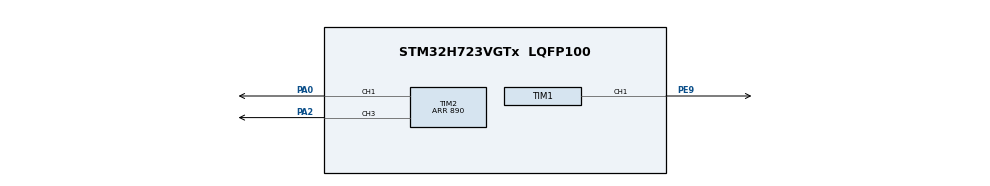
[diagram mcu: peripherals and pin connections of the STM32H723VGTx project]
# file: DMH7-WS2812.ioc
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CORTEX_M7.default_mode_Activation=1
Dma.Request0=TIM2_CH1
Dma.Request1=TIM2_CH3
Dma.Request2=TIM1_CH1
Dma.TIM1_CH1.2.Direction=DMA_MEMORY_TO_PERIPH
Dma.TIM1_CH1.2.EventEnable=DISABLE
Dma.TIM1_CH1.2.FIFOMode=DMA_FIFOMODE_DISABLE
Dma.TIM1_CH1.2.Instance=DMA1_Stream0
Dma.TIM1_CH1.2.MemDataAlignment=DMA_MDATAALIGN_HALFWORD
Dma.TIM1_CH1.2.MemInc=DMA_MINC_ENABLE
Dma.TIM1_CH1.2.Mode=DMA_NORMAL
Dma.TIM1_CH1.2.PeriphDataAlignment=DMA_PDATAALIGN_HALFWORD
Dma.TIM1_CH1.2.PeriphInc=DMA_PINC_DISABLE
Dma.TIM1_CH1.2.Polarity=HAL_DMAMUX_REQ_GEN_RISING
Dma.TIM1_CH1.2.Priority=DMA_PRIORITY_LOW
Dma.TIM1_CH1.2.RequestNumber=1
Dma.TIM1_CH1.2.SignalID=NONE
Dma.TIM1_CH1.2.SyncEnable=DISABLE
Dma.TIM1_CH1.2.SyncPolarity=HAL_DMAMUX_SYNC_NO_EVENT
Dma.TIM1_CH1.2.SyncRequestNumber=1
Dma.TIM1_CH1.2.SyncSignalID=NONE
Dma.TIM2_CH1.0.Direction=DMA_MEMORY_TO_PERIPH
Dma.TIM2_CH1.0.EventEnable=DISABLE
Dma.TIM2_CH1.0.FIFOMode=DMA_FIFOMODE_ENABLE
Dma.TIM2_CH1.0.FIFOThreshold=DMA_FIFO_THRESHOLD_FULL
Dma.TIM2_CH1.0.Instance=DMA2_Stream0
Dma.TIM2_CH1.0.MemBurst=DMA_MBURST_SINGLE
Dma.TIM2_CH1.0.MemDataAlignment=DMA_MDATAALIGN_HALFWORD
Dma.TIM2_CH1.0.MemInc=DMA_MINC_ENABLE
Dma.TIM2_CH1.0.Mode=DMA_CIRCULAR
Dma.TIM2_CH1.0.PeriphBurst=DMA_PBURST_SINGLE
Dma.TIM2_CH1.0.PeriphDataAlignment=DMA_PDATAALIGN_HALFWORD
Dma.TIM2_CH1.0.PeriphInc=DMA_PINC_DISABLE
Dma.TIM2_CH1.0.Polarity=HAL_DMAMUX_REQ_GEN_RISING
Dma.TIM2_CH1.0.Priority=DMA_PRIORITY_VERY_HIGH
Dma.TIM2_CH1.0.RequestNumber=1
Dma.TIM2_CH1.0.SignalID=NONE
Dma.TIM2_CH1.0.SyncEnable=DISABLE
Dma.TIM2_CH1.0.SyncPolarity=HAL_DMAMUX_SYNC_NO_EVENT
Dma.TIM2_CH1.0.SyncRequestNumber=1
Dma.TIM2_CH1.0.SyncSignalID=NONE
Dma.TIM2_CH3.1.Direction=DMA_MEMORY_TO_PERIPH
Dma.TIM2_CH3.1.EventEnable=DISABLE
Dma.TIM2_CH3.1.FIFOMode=DMA_FIFOMODE_ENABLE
Dma.TIM2_CH3.1.FIFOThreshold=DMA_FIFO_THRESHOLD_FULL
Dma.TIM2_CH3.1.Instance=DMA1_Stream1
Dma.TIM2_CH3.1.MemBurst=DMA_MBURST_SINGLE
Dma.TIM2_CH3.1.MemDataAlignment=DMA_MDATAALIGN_WORD
Dma.TIM2_CH3.1.MemInc=DMA_MINC_ENABLE
Dma.TIM2_CH3.1.Mode=DMA_CIRCULAR
Dma.TIM2_CH3.1.PeriphBurst=DMA_PBURST_SINGLE
Dma.TIM2_CH3.1.PeriphDataAlignment=DMA_PDATAALIGN_WORD
Dma.TIM2_CH3.1.PeriphInc=DMA_PINC_DISABLE
Dma.TIM2_CH3.1.Polarity=HAL_DMAMUX_REQ_GEN_RISING
Dma.TIM2_CH3.1.Priority=DMA_PRIORITY_VERY_HIGH
Dma.TIM2_CH3.1.RequestNumber=1
Dma.TIM2_CH3.1.SignalID=NONE
Dma.TIM2_CH3.1.SyncEnable=DISABLE
Dma.TIM2_CH3.1.SyncPolarity=HAL_DMAMUX_SYNC_NO_EVENT
Dma.TIM2_CH3.1.SyncRequestNumber=1
Dma.TIM2_CH3.1.SyncSignalID=NONE
Mcu.Family=STM32H7
Mcu.Name=STM32H723VGTx
Mcu.Package=LQFP100
NVIC.DMA1_Stream0_IRQn=true\:0\:0\:false\:false\:true\:false\:true\:true
NVIC.DMA1_Stream1_IRQn=true\:0\:0\:false\:false\:true\:false\:true\:true
NVIC.DMA2_Stream0_IRQn=true\:1\:0\:true\:false\:true\:false\:true\:true
NVIC.PriorityGroup=NVIC_PRIORITYGROUP_4
PA0.Signal=S_TIM2_CH1_ETR
PA2.Signal=S_TIM2_CH3
PE9.Signal=S_TIM1_CH1
PH0-OSC_IN.Mode=HSE-External-Oscillator
PH0-OSC_IN.Signal=RCC_OSC_IN
PH1-OSC_OUT.Mode=HSE-External-Oscillator
PH1-OSC_OUT.Signal=RCC_OSC_OUT
ProjectManager.HeapSize=0x200
ProjectManager.StackSize=0x400
ProjectManager.TargetToolchain=STM32CubeIDE
RCC.ADCFreq_Value=48375000
RCC.APB1Freq_Value=36000000
RCC.APB2Freq_Value=36000000
RCC.APB3Freq_Value=36000000
RCC.APB4Freq_Value=36000000
RCC.CortexFreq_Value=72000000
RCC.D1PPRE=RCC_APB3_DIV2
RCC.D2PPRE1=RCC_APB1_DIV2
RCC.D2PPRE2=RCC_APB2_DIV2
RCC.D3PPRE=RCC_APB4_DIV2
RCC.DIVM1=2
RCC.DIVN1=18
RCC.DIVP1=3
RCC.HCLKFreq_Value=72000000
RCC.HSE_VALUE=24000000
RCC.PLL2FRACN=0
RCC.PLL2_VCI_Range-AdvancedSettings=RCC_PLL2VCIRANGE_3
RCC.PLL3FRACN=0
RCC.PLLFRACN=0
RCC.PLLSourceVirtual=RCC_PLLSOURCE_HSE
RCC.SYSCLKFreq_VALUE=72000000
RCC.SYSCLKSource=RCC_SYSCLKSOURCE_PLLCLK
RCC.USART16Enable-ClockTree=true
RCC.USBFreq_Value=108000000
SH.S_TIM1_CH1.0=TIM1_CH1,PWM Generation1 CH1
SH.S_TIM2_CH1_ETR.0=TIM2_CH1,PWM Generation1 CH1
SH.S_TIM2_CH3.0=TIM2_CH3,PWM Generation3 CH3
TIM1.Channel-PWM\ Generation1\ CH1=TIM_CHANNEL_1
TIM1.Period=89
TIM2.Channel-PWM\ Generation1\ CH1=TIM_CHANNEL_1
TIM2.Channel-PWM\ Generation3\ CH3=TIM_CHANNEL_3
TIM2.Period=890
TIM2.Pulse-PWM\ Generation1\ CH1=20
TIM2.Pulse-PWM\ Generation3\ CH3=20
VP_MEMORYMAP_VS_MEMORYMAP.Mode=CurAppReg
board=custom

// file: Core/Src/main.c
/* USER CODE BEGIN Header */
/**
  ******************************************************************************
  * @file           : main.c
  * @brief          : Main program body
  ******************************************************************************
  * @attention
  *
  * Copyright (c) 2024 STMicroelectronics.
  * All rights reserved.
  *
  * This software is licensed under terms that can be found in the LICENSE file
  * in the root directory of this software component.
  * If no LICENSE file comes with this software, it is provided AS-IS.
  *
  ******************************************************************************
  */
/* USER CODE END Header */
#include "main.h"
#include "dma.h"
#include "memorymap.h"
#include "tim.h"
#include "gpio.h"

/* USER CODE BEGIN Includes */
#include "WS2812.h"
/* USER CODE END Includes */

void SystemClock_Config(void);

int main(void)
{

  /* MCU Configuration--------------------------------------------------------*/

  /* Reset of all peripherals, Initializes the Flash interface and the Systick. */
  HAL_Init();

  /* Configure the system clock */
  SystemClock_Config();

  /* Initialize all configured peripherals */
  MX_GPIO_Init();
  MX_DMA_Init();
  MX_TIM2_Init();
  MX_TIM1_Init();
  /* USER CODE BEGIN 2 */
  WS2812_Init();
  float circle_idx[][5] = {
    {8.4,0,15,44.5,78},
    {7.4,103,131.5,158.5,187.4},
    {6.4,211.5,235,258.5,283.4},
    {5.4,302.4,324.5,345.5,365.4},
    {4.4,383.4,400,417,435.4},
    {3.4,448.4,463,477,491},
    {2.4,501.4,512.5,523,532.4},
    {1.4,540,546.5,553,560},
    {0.4,566,568,570,573.6},
    {0,575,0,0,0},
  };
  // static uint16_t led_block[1][2] = {0};
  static uint16_t led_block[10*4+4][2] = {0};

  static uint32_t color = 0x00FF0000;

  WS2812_Start();
  /* USER CODE END 2 */

  /* Infinite loop */
  /* USER CODE BEGIN WHILE */
  while (1)
  {
    HAL_TIM_PWM_Stop_DMA(&htim1, TIM_CHANNEL_1);
    WS2812_Init();
    for (int i = 0; i < sizeof(circle_idx)/sizeof(circle_idx[0]); i++){
      for (int j = 0; j < sizeof(circle_idx[0])/sizeof(circle_idx[0][0]); j++){
        if(circle_idx[i][j+1] == 0.0) continue;
        led_block[i*4+j][0] = circle_idx[i][j+1] - circle_idx[i][0];
        led_block[i*4+j][1] = circle_idx[i][j+1] + circle_idx[i][0];
      }
    }
    uint8_t block_idx = 0,block_flag = 1;
    for (int i = 0; i < LED_NUM; i++){
      if( block_flag &&  i >= led_block[block_idx][0] && i <= led_block[block_idx][1])
        WS2812_Set(i, color);
      else
        WS2812_Set(i, 0x00);
      while (block_flag && i>led_block[block_idx][1])  {
        block_idx++;
        if (block_idx > sizeof(led_block)/4) block_flag = 0;
      }

    }
    WS2812_Start();
    HAL_Delay(1000);
    /* USER CODE END WHILE */

  }
}

void SystemClock_Config(void)
{
  RCC_OscInitTypeDef RCC_OscInitStruct = {0};
  RCC_ClkInitTypeDef RCC_ClkInitStruct = {0};

  /** Supply configuration update enable
  */
  HAL_PWREx_ConfigSupply(PWR_LDO_SUPPLY);

  /** Configure the main internal regulator output voltage
  */
  __HAL_PWR_VOLTAGESCALING_CONFIG(PWR_REGULATOR_VOLTAGE_SCALE3);

  while(!__HAL_PWR_GET_FLAG(PWR_FLAG_VOSRDY)) {}

  /** Initializes the RCC Oscillators according to the specified parameters
  * in the RCC_OscInitTypeDef structure.
  */
  RCC_OscInitStruct.OscillatorType = RCC_OSCILLATORTYPE_HSE;
  RCC_OscInitStruct.HSEState = RCC_HSE_ON;
  RCC_OscInitStruct.PLL.PLLState = RCC_PLL_ON;
  RCC_OscInitStruct.PLL.PLLSource = RCC_PLLSOURCE_HSE;
  RCC_OscInitStruct.PLL.PLLM = 2;
  RCC_OscInitStruct.PLL.PLLN = 18;
  RCC_OscInitStruct.PLL.PLLP = 3;
  RCC_OscInitStruct.PLL.PLLQ = 2;
  RCC_OscInitStruct.PLL.PLLR = 2;
  RCC_OscInitStruct.PLL.PLLRGE = RCC_PLL1VCIRANGE_3;
  RCC_OscInitStruct.PLL.PLLVCOSEL = RCC_PLL1VCOWIDE;
  RCC_OscInitStruct.PLL.PLLFRACN = 0;
  if (HAL_RCC_OscConfig(&RCC_OscInitStruct) != HAL_OK)
  {
    Error_Handler();
  }

  /** Initializes the CPU, AHB and APB buses clocks
  */
  RCC_ClkInitStruct.ClockType = RCC_CLOCKTYPE_HCLK|RCC_CLOCKTYPE_SYSCLK
                              |RCC_CLOCKTYPE_PCLK1|RCC_CLOCKTYPE_PCLK2
                              |RCC_CLOCKTYPE_D3PCLK1|RCC_CLOCKTYPE_D1PCLK1;
  RCC_ClkInitStruct.SYSCLKSource = RCC_SYSCLKSOURCE_PLLCLK;
  RCC_ClkInitStruct.SYSCLKDivider = RCC_SYSCLK_DIV1;
  RCC_ClkInitStruct.AHBCLKDivider = RCC_HCLK_DIV1;
  RCC_ClkInitStruct.APB3CLKDivider = RCC_APB3_DIV2;
  RCC_ClkInitStruct.APB1CLKDivider = RCC_APB1_DIV2;
  RCC_ClkInitStruct.APB2CLKDivider = RCC_APB2_DIV2;
  RCC_ClkInitStruct.APB4CLKDivider = RCC_APB4_DIV2;

  if (HAL_RCC_ClockConfig(&RCC_ClkInitStruct, FLASH_LATENCY_2) != HAL_OK)
  {
    Error_Handler();
  }
}

void Error_Handler(void)
{
  __disable_irq();
  while (1)
  {
  }
}
